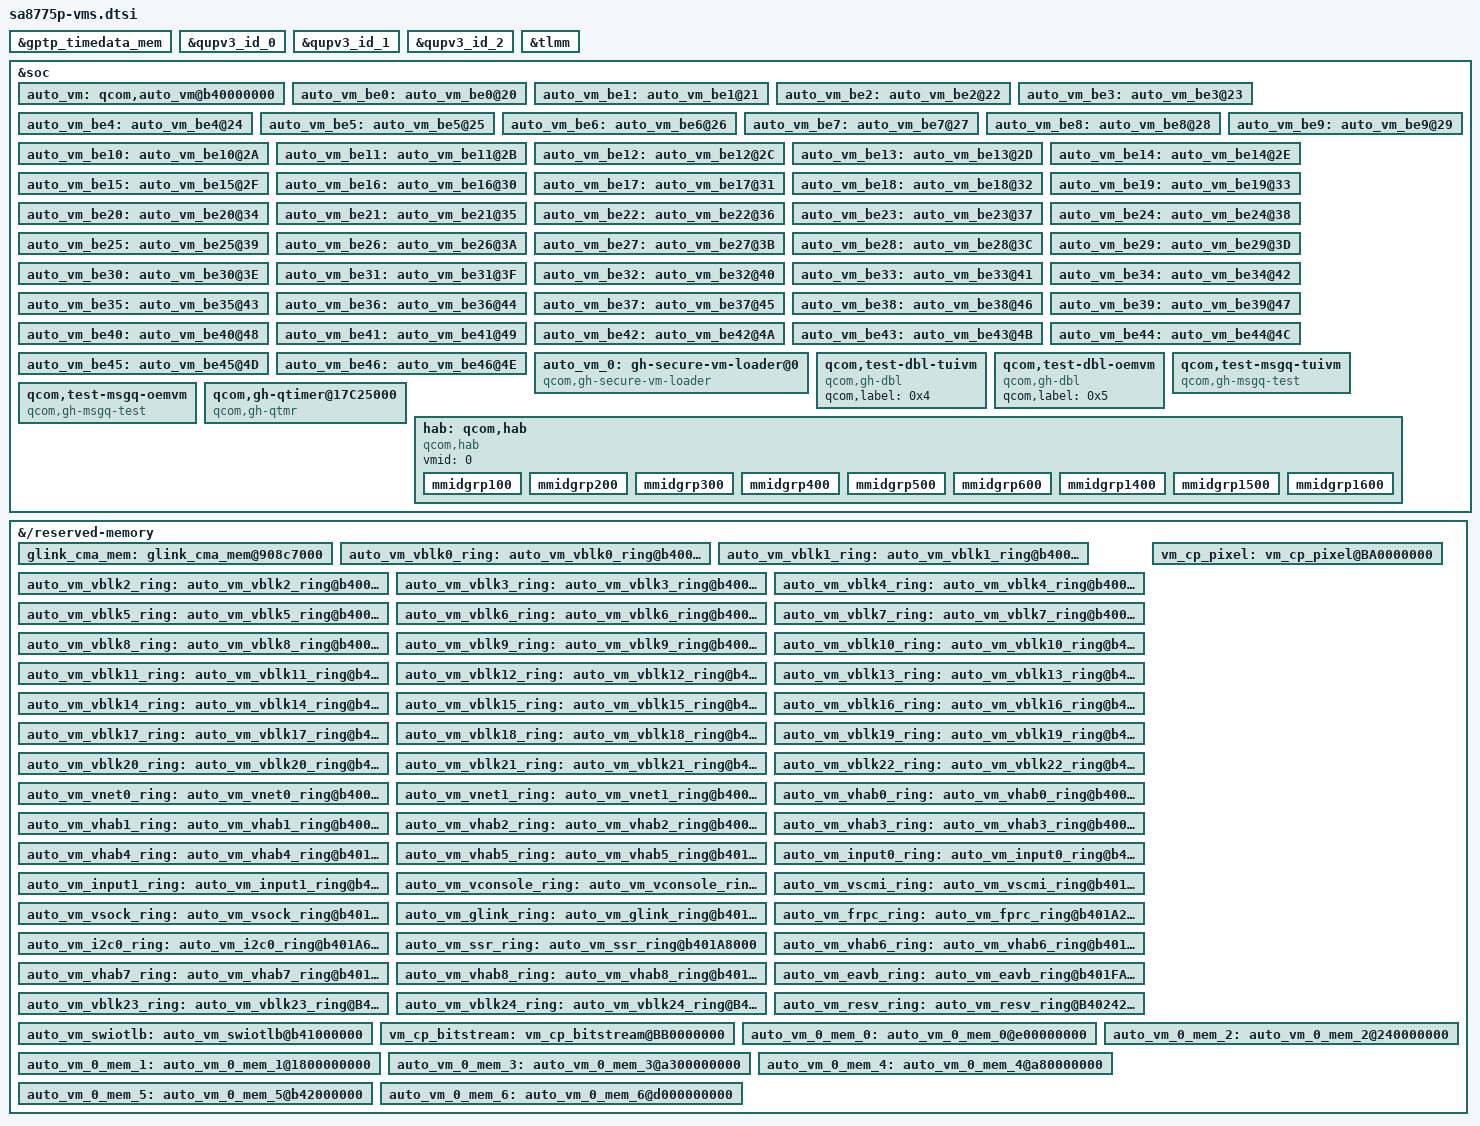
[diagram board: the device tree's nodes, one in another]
// SPDX-License-Identifier: BSD-3-Clause
/*
 * Copyright (c) Qualcomm Technologies, Inc. and/or its subsidiaries.
 */

#include <dt-bindings/firmware/qcom-shmem.h>
#include "sa8775p-vms-uscmi.dtsi"

&gptp_timedata_mem {
	qcom,is-shared;
	gunyah-label = <0x61>;
};

&qupv3_id_0 {
	reg = <0x0 0x009c0000 0x0 0x1000>;
	qcom,is-shared;
	qcom,is-iomem;
	gunyah-label = <0x7F>;
	qcom,dst-vmids = <AC_VM_GVM_1 AC_VM_GVM_2>;
	qcom,dst-perms = <QCOM_PERM_RW QCOM_PERM_RW>;
};

&qupv3_id_1 {
	reg = <0x0 0x00ac0000 0x0 0x1000>;
	qcom,is-shared;
	qcom,is-iomem;
	gunyah-label = <0x80>;
	qcom,dst-vmids = <AC_VM_GVM_1 AC_VM_GVM_2>;
	qcom,dst-perms = <QCOM_PERM_RW QCOM_PERM_RW>;
};

&qupv3_id_2 {
	reg = <0x0 0x008c0000 0x0 0x1000>;
	qcom,is-shared;
	qcom,is-iomem;
	gunyah-label = <0x81>;
	qcom,dst-vmids = <AC_VM_GVM_1 AC_VM_GVM_2>;
	qcom,dst-perms = <QCOM_PERM_RW QCOM_PERM_RW>;
};

&tlmm {
	qcom,is-shared;
	qcom,is-iomem;
	gunyah-label = <0x7E>;
	qcom,dst-vmids = <AC_VM_GVM_1 AC_VM_GVM_2>;
	qcom,dst-perms = <QCOM_PERM_RW QCOM_PERM_RW>;
};

&soc {
	auto_vm: qcom,auto_vm@b40000000 {
		reg = <0xb 0x40000000 0x0 0x3000000>;
		vm_name = "autoghgvm";
		shared-buffers = <&auto_vm_vblk0_ring
				&auto_vm_vblk1_ring
				&auto_vm_vblk2_ring
				&auto_vm_vblk3_ring
				&auto_vm_vblk4_ring
				&auto_vm_vblk5_ring
				&auto_vm_vblk6_ring
				&auto_vm_vblk7_ring
				&auto_vm_vblk8_ring
				&auto_vm_vblk9_ring
				&auto_vm_vblk10_ring
				&auto_vm_vblk11_ring
				&auto_vm_vblk12_ring
				&auto_vm_vblk13_ring
				&auto_vm_vblk14_ring
				&auto_vm_vblk15_ring
				&auto_vm_vblk16_ring
				&auto_vm_vblk17_ring
				&auto_vm_vblk18_ring
				&auto_vm_vblk19_ring
				&auto_vm_vblk20_ring
				&auto_vm_vblk21_ring
				&auto_vm_vblk22_ring
				&auto_vm_vblk23_ring
				&auto_vm_vblk24_ring
				&auto_vm_vnet0_ring
				&auto_vm_vnet1_ring
				&auto_vm_vhab0_ring
				&auto_vm_vhab1_ring
				&auto_vm_vhab2_ring
				&auto_vm_vhab3_ring
				&auto_vm_vhab4_ring
				&auto_vm_vhab5_ring
				&auto_vm_vhab6_ring
				&auto_vm_vhab7_ring
				&auto_vm_vhab8_ring
				&auto_vm_input0_ring
				&auto_vm_input1_ring
				&auto_vm_vconsole_ring
				&auto_vm_vscmi_ring
				&auto_vm_vsock_ring
				&auto_vm_glink_ring
				&auto_vm_frpc_ring
				&auto_vm_i2c0_ring
				&auto_vm_ssr_ring
				&auto_vm_eavb_ring
				&auto_vm_resv_ring
				&auto_vm_swiotlb>;
	};

	auto_vm_be0: auto_vm_be0@20 {
		qcom,vm = <&auto_vm>;
		qcom,label = <0x20>;
	};

	auto_vm_be1: auto_vm_be1@21 {
		qcom,vm = <&auto_vm>;
		qcom,label = <0x21>;
	};

	auto_vm_be2: auto_vm_be2@22 {
		qcom,vm = <&auto_vm>;
		qcom,label = <0x22>;
	};

	auto_vm_be3: auto_vm_be3@23 {
		qcom,vm = <&auto_vm>;
		qcom,label = <0x23>;
	};

	auto_vm_be4: auto_vm_be4@24 {
		qcom,vm = <&auto_vm>;
		qcom,label = <0x24>;
	};

	auto_vm_be5: auto_vm_be5@25 {
		qcom,vm = <&auto_vm>;
		qcom,label = <0x25>;
	};

	auto_vm_be6: auto_vm_be6@26 {
		qcom,vm = <&auto_vm>;
		qcom,label = <0x26>;
	};

	auto_vm_be7: auto_vm_be7@27 {
		qcom,vm = <&auto_vm>;
		qcom,label = <0x27>;
	};

	auto_vm_be8: auto_vm_be8@28 {
		qcom,vm = <&auto_vm>;
		qcom,label = <0x28>;
	};

	auto_vm_be9: auto_vm_be9@29 {
		qcom,vm = <&auto_vm>;
		qcom,label = <0x29>;
	};

	auto_vm_be10: auto_vm_be10@2A {
		qcom,vm = <&auto_vm>;
		qcom,label = <0x2A>;
	};

	auto_vm_be11: auto_vm_be11@2B {
		qcom,vm = <&auto_vm>;
		qcom,label = <0x2B>;
	};

	auto_vm_be12: auto_vm_be12@2C {
		qcom,vm = <&auto_vm>;
		qcom,label = <0x2C>;
	};

	auto_vm_be13: auto_vm_be13@2D {
		qcom,vm = <&auto_vm>;
		qcom,label = <0x2D>;
	};

	auto_vm_be14: auto_vm_be14@2E {
		qcom,vm = <&auto_vm>;
		qcom,label = <0x2E>;
	};

	auto_vm_be15: auto_vm_be15@2F {
		qcom,vm = <&auto_vm>;
		qcom,label = <0x2F>;
	};

	auto_vm_be16: auto_vm_be16@30 {
		qcom,vm = <&auto_vm>;
		qcom,label = <0x30>;
	};

	auto_vm_be17: auto_vm_be17@31 {
		qcom,vm = <&auto_vm>;
		qcom,label = <0x31>;
	};

	auto_vm_be18: auto_vm_be18@32 {
		qcom,vm = <&auto_vm>;
		qcom,label = <0x32>;
	};

	auto_vm_be19: auto_vm_be19@33 {
		qcom,vm = <&auto_vm>;
		qcom,label = <0x33>;
	};

	auto_vm_be20: auto_vm_be20@34 {
		qcom,vm = <&auto_vm>;
		qcom,label = <0x34>;
	};

	auto_vm_be21: auto_vm_be21@35 {
		qcom,vm = <&auto_vm>;
		qcom,label = <0x35>;
	};

	auto_vm_be22: auto_vm_be22@36 {
		qcom,vm = <&auto_vm>;
		qcom,label = <0x36>;
	};

	auto_vm_be23: auto_vm_be23@37 {
		qcom,vm = <&auto_vm>;
		qcom,label = <0x37>;
	};

	auto_vm_be24: auto_vm_be24@38 {
		qcom,vm = <&auto_vm>;
		qcom,label = <0x38>;
	};

	auto_vm_be25: auto_vm_be25@39 {
		qcom,vm = <&auto_vm>;
		qcom,label = <0x39>;
	};

	auto_vm_be26: auto_vm_be26@3A {
		qcom,vm = <&auto_vm>;
		qcom,label = <0x3A>;
	};

	auto_vm_be27: auto_vm_be27@3B {
		qcom,vm = <&auto_vm>;
		qcom,label = <0x3B>;
	};

	auto_vm_be28: auto_vm_be28@3C {
		qcom,vm = <&auto_vm>;
		qcom,label = <0x3C>;
	};

	auto_vm_be29: auto_vm_be29@3D {
		qcom,vm = <&auto_vm>;
		qcom,label = <0x3D>;
	};

	auto_vm_be30: auto_vm_be30@3E {
		qcom,vm = <&auto_vm>;
		qcom,label = <0x3E>;
	};

	auto_vm_be31: auto_vm_be31@3F {
		qcom,vm = <&auto_vm>;
		qcom,label = <0x3F>;
	};

	auto_vm_be32: auto_vm_be32@40 {
		qcom,vm = <&auto_vm>;
		qcom,label = <0x40>;
	};

	auto_vm_be33: auto_vm_be33@41 {
		qcom,vm = <&auto_vm>;
		qcom,label = <0x41>;
	};

	auto_vm_be34: auto_vm_be34@42 {
		qcom,vm = <&auto_vm>;
		qcom,label = <0x42>;
	};

	auto_vm_be35: auto_vm_be35@43 {
		qcom,vm = <&auto_vm>;
		qcom,label = <0x43>;
	};

	auto_vm_be36: auto_vm_be36@44 {
		qcom,vm = <&auto_vm>;
		qcom,label = <0x44>;
	};

	auto_vm_be37: auto_vm_be37@45 {
		qcom,vm = <&auto_vm>;
		qcom,label = <0x45>;
	};

	auto_vm_be38: auto_vm_be38@46 {
		qcom,vm = <&auto_vm>;
		qcom,label = <0x46>;
	};

	auto_vm_be39: auto_vm_be39@47 {
		qcom,vm = <&auto_vm>;
		qcom,label = <0x47>;
	};

	auto_vm_be40: auto_vm_be40@48 {
		qcom,vm = <&auto_vm>;
		qcom,label = <0x48>;
	};

	auto_vm_be41: auto_vm_be41@49 {
		qcom,vm = <&auto_vm>;
		qcom,label = <0x49>;
	};

	auto_vm_be42: auto_vm_be42@4A {
		qcom,vm = <&auto_vm>;
		qcom,label = <0x4A>;
	};

	auto_vm_be43: auto_vm_be43@4B {
		qcom,vm = <&auto_vm>;
		qcom,label = <0x4B>;
	};

	auto_vm_be44: auto_vm_be44@4C {
		qcom,vm = <&auto_vm>;
		qcom,label = <0x4C>;
	};

	auto_vm_be45: auto_vm_be45@4D {
		qcom,vm = <&auto_vm>;
		qcom,label = <0x4D>;
	};

	auto_vm_be46: auto_vm_be46@4E {
		qcom,vm = <&auto_vm>;
		qcom,label = <0x4E>;
	};

	auto_vm_0: gh-secure-vm-loader@0 {
		compatible = "qcom,gh-secure-vm-loader";
		qcom,pas-id = <44>;
		qcom,vmid = <52>;
		qcom,firmware-name = "autoghgvm";
		qcom,firmware-index = <0>;
		memory-region = <&auto_vm_0_mem_0 &auto_vm_0_mem_1 &auto_vm_0_mem_2 &auto_vm_0_mem_3 &auto_vm_0_mem_4 &auto_vm_0_mem_5 &auto_vm_0_mem_6>;
		shared-regions = <&glink_cma_mem &gptp_timedata_mem &vm_cp_pixel &vm_cp_bitstream &tlmm &qupv3_id_0 &qupv3_id_1 &qupv3_id_2>;
		enable-gvm-dump;
		virtio-backends = <&auto_vm_be0
				&auto_vm_be1
				&auto_vm_be2
				&auto_vm_be3
				&auto_vm_be4
				&auto_vm_be5
				&auto_vm_be6
				&auto_vm_be7
				&auto_vm_be8
				&auto_vm_be9
				&auto_vm_be10
				&auto_vm_be11
				&auto_vm_be12
				&auto_vm_be13
				&auto_vm_be14
				&auto_vm_be15
				&auto_vm_be16
				&auto_vm_be17
				&auto_vm_be18
				&auto_vm_be19
				&auto_vm_be20
				&auto_vm_be21
				&auto_vm_be22
				&auto_vm_be23
				&auto_vm_be24
				&auto_vm_be25
				&auto_vm_be26
				&auto_vm_be27
				&auto_vm_be28
				&auto_vm_be29
				&auto_vm_be30
				&auto_vm_be31
				&auto_vm_be32
				&auto_vm_be33
				&auto_vm_be34
				&auto_vm_be35
				&auto_vm_be36
				&auto_vm_be37
				&auto_vm_be38
				&auto_vm_be39
				&auto_vm_be40
				&auto_vm_be41
				&auto_vm_be42
				&auto_vm_be43
				&auto_vm_be44
				&auto_vm_be45
				&auto_vm_be46
				>;
	};

	qcom,test-dbl-tuivm {
		compatible = "qcom,gh-dbl";
		qcom,label = <0x4>;
	};

	qcom,test-dbl-oemvm {
		compatible = "qcom,gh-dbl";
		qcom,label = <0x5>;
	};

	qcom,test-msgq-tuivm {
		compatible = "qcom,gh-msgq-test";
		gunyah-label = <4>;
		qcom,primary;
	};

	qcom,test-msgq-oemvm {
		compatible = "qcom,gh-msgq-test";
		gunyah-label = <5>;
		qcom,primary;
	};

	qcom,gh-qtimer@17C25000 {
		compatible = "qcom,gh-qtmr";
		reg = <0x0 0x17C25000 0x0 0x1000>;
		reg-names = "qtmr-base";
		interrupts = <GIC_SPI 10 IRQ_TYPE_LEVEL_HIGH>;
		interrupt-names = "qcom,qtmr-intr";
		qcom,primary;
	};
};

&{/reserved-memory} {
	#address-cells = <2>;
	#size-cells = <2>;
	ranges;

	glink_cma_mem: glink_cma_mem@908c7000 {
		no-map;
		reg = <0x0 0x908c7000 0x0 0x12000>;
		qcom,dst-vmids = <AC_VM_CDSP_Q6_ELF>;
		qcom,dst-perms = <QCOM_PERM_RWX>;
		gunyah-label = <0x60>;
	};

	auto_vm_vblk0_ring: auto_vm_vblk0_ring@b40000000 {
		no-map;
		reg = <0xb 0x40000000 0x0 0x4000>;
		gunyah-label = <0x20>;
	};

	auto_vm_vblk1_ring: auto_vm_vblk1_ring@b40004000 {
		no-map;
		reg = <0xb 0x40004000 0x0 0x4000>;
		gunyah-label = <0x21>;
	};

	auto_vm_vblk2_ring: auto_vm_vblk2_ring@b40008000 {
		no-map;
		reg = <0xb 0x40008000 0x0 0x4000>;
		gunyah-label = <0x22>;
	};

	auto_vm_vblk3_ring: auto_vm_vblk3_ring@b4000C000 {
		no-map;
		reg = <0xb 0x4000C000 0x0 0x4000>;
		gunyah-label = <0x23>;
	};

	auto_vm_vblk4_ring: auto_vm_vblk4_ring@b40010000 {
		no-map;
		reg = <0xb 0x40010000 0x0 0x4000>;
		gunyah-label = <0x24>;
	};

	auto_vm_vblk5_ring: auto_vm_vblk5_ring@b40014000 {
		no-map;
		reg = <0xb 0x40014000 0x0 0x4000>;
		gunyah-label = <0x25>;
	};

	auto_vm_vblk6_ring: auto_vm_vblk6_ring@b40018000 {
		no-map;
		reg = <0xb 0x40018000 0x0 0x4000>;
		gunyah-label = <0x26>;
	};

	auto_vm_vblk7_ring: auto_vm_vblk7_ring@b4001C000 {
		no-map;
		reg = <0xb 0x4001C000 0x0 0x4000>;
		gunyah-label = <0x27>;
	};

	auto_vm_vblk8_ring: auto_vm_vblk8_ring@b40020000 {
		no-map;
		reg = <0xb 0x40020000 0x0 0x4000>;
		gunyah-label = <0x28>;
	};

	auto_vm_vblk9_ring: auto_vm_vblk9_ring@b40024000 {
		no-map;
		reg = <0xb 0x40024000 0x0 0x4000>;
		gunyah-label = <0x29>;
	};

	auto_vm_vblk10_ring: auto_vm_vblk10_ring@b40028000 {
		no-map;
		reg = <0xb 0x40028000 0x0 0x4000>;
		gunyah-label = <0x2A>;
	};

	auto_vm_vblk11_ring: auto_vm_vblk11_ring@b4002C000 {
		no-map;
		reg = <0xb 0x4002C000 0x0 0x4000>;
		gunyah-label = <0x2B>;
	};

	auto_vm_vblk12_ring: auto_vm_vblk12_ring@b40030000 {
		no-map;
		reg = <0xb 0x40030000 0x0 0x4000>;
		gunyah-label = <0x2C>;
	};

	auto_vm_vblk13_ring: auto_vm_vblk13_ring@b40034000 {
		no-map;
		reg = <0xb 0x40034000 0x0 0x4000>;
		gunyah-label = <0x2D>;
	};

	auto_vm_vblk14_ring: auto_vm_vblk14_ring@b40038000 {
		no-map;
		reg = <0xb 0x40038000 0x0 0x4000>;
		gunyah-label = <0x2E>;
	};

	auto_vm_vblk15_ring: auto_vm_vblk15_ring@b4003C000 {
		no-map;
		reg = <0xb 0x4003C000 0x0 0x4000>;
		gunyah-label = <0x2F>;
	};

	auto_vm_vblk16_ring: auto_vm_vblk16_ring@b40040000 {
		no-map;
		reg = <0xb 0x40040000 0x0 0x4000>;
		gunyah-label = <0x30>;
	};

	auto_vm_vblk17_ring: auto_vm_vblk17_ring@b40044000 {
		no-map;
		reg = <0xb 0x40044000 0x0 0x4000>;
		gunyah-label = <0x31>;
	};

	auto_vm_vblk18_ring: auto_vm_vblk18_ring@b40048000 {
		no-map;
		reg = <0xb 0x40048000 0x0 0x4000>;
		gunyah-label = <0x32>;
	};

	auto_vm_vblk19_ring: auto_vm_vblk19_ring@b4004C000 {
		no-map;
		reg = <0xb 0x4004C000 0x0 0x4000>;
		gunyah-label = <0x33>;
	};

	auto_vm_vblk20_ring: auto_vm_vblk20_ring@b40050000 {
		no-map;
		reg = <0xb 0x40050000 0x0 0x4000>;
		gunyah-label = <0x34>;
	};

	auto_vm_vblk21_ring: auto_vm_vblk21_ring@b40054000 {
		no-map;
		reg = <0xb 0x40054000 0x0 0x4000>;
		gunyah-label = <0x35>;
	};

	auto_vm_vblk22_ring: auto_vm_vblk22_ring@b40058000 {
		no-map;
		reg = <0xb 0x40058000 0x0 0x4000>;
		gunyah-label = <0x36>;
	};

	auto_vm_vnet0_ring: auto_vm_vnet0_ring@b4005C000 {
		no-map;
		reg = <0xb 0x4005C000 0x0 0x8000>;
		gunyah-label = <0x37>;
	};

	auto_vm_vnet1_ring: auto_vm_vnet1_ring@b40064000 {
		no-map;
		reg = <0xb 0x40064000 0x0 0x8000>;
		gunyah-label = <0x38>;
	};

	auto_vm_vhab0_ring: auto_vm_vhab0_ring@b4006C000 {
		no-map;
		reg = <0xb 0x4006C000 0x0 0x10000>;
		gunyah-label = <0x39>;
	};

	auto_vm_vhab1_ring: auto_vm_vhab1_ring@b4007C000 {
		no-map;
		reg = <0xb 0x4007C000 0x0 0x10000>;
		gunyah-label = <0x3A>;
	};

	auto_vm_vhab2_ring: auto_vm_vhab2_ring@b4008C000 {
		no-map;
		reg = <0xb 0x4008C000 0x0 0x40000>;
		gunyah-label = <0x3B>;
	};

	auto_vm_vhab3_ring: auto_vm_vhab3_ring@b400CC000 {
		no-map;
		reg = <0xb 0x400CC000 0x0 0x50000>;
		gunyah-label = <0x3C>;
	};

	auto_vm_vhab4_ring: auto_vm_vhab4_ring@b4011C000 {
		no-map;
		reg = <0xb 0x4011C000 0x0 0x30000>;
		gunyah-label = <0x3D>;
	};

	auto_vm_vhab5_ring: auto_vm_vhab5_ring@b4014C000 {
		no-map;
		reg = <0xb 0x4014C000 0x0 0x30000>;
		gunyah-label = <0x3E>;
	};

	auto_vm_input0_ring: auto_vm_input0_ring@b4017C000 {
		no-map;
		reg = <0xb 0x4017C000 0x0 0x4000>;
		gunyah-label = <0x3F>;
	};

	auto_vm_input1_ring: auto_vm_input1_ring@b40180000 {
		no-map;
		reg = <0xb 0x40180000 0x0 0x4000>;
		gunyah-label = <0x40>;
	};

	auto_vm_vconsole_ring: auto_vm_vconsole_ring@b40184000 {
		no-map;
		reg = <0xb 0x40184000 0x0 0x8000>;
		gunyah-label = <0x41>;
	};

	auto_vm_vscmi_ring: auto_vm_vscmi_ring@b4018C000 {
		no-map;
		reg = <0xb 0x4018C000 0x0 0x8000>;
		gunyah-label = <0x42>;
	};

	auto_vm_vsock_ring: auto_vm_vsock_ring@b40194000 {
		no-map;
		reg = <0xb 0x40194000 0x0 0xC000>;
		gunyah-label = <0x43>;
	};

	auto_vm_glink_ring: auto_vm_glink_ring@b401A0000 {
		no-map;
		reg = <0xb 0x401A0000 0x0 0x2000>;
		gunyah-label = <0x44>;
	};

	auto_vm_frpc_ring: auto_vm_fprc_ring@b401A2000 {
		no-map;
		reg = <0xb 0x401A2000 0x0 0x4000>;
		gunyah-label = <0x45>;
	};

	auto_vm_i2c0_ring: auto_vm_i2c0_ring@b401A6000 {
		no-map;
		reg = <0xb 0x401A6000 0x0 0x2000>;
		gunyah-label = <0x46>;
	};

	auto_vm_ssr_ring: auto_vm_ssr_ring@b401A8000 {
		no-map;
		reg = <0xb 0x401A8000 0x0 0x2000>;
		gunyah-label = <0x47>;
	};

	auto_vm_vhab6_ring: auto_vm_vhab6_ring@b401AA000 {
		no-map;
		reg = <0xb 0x401AA000 0x0 0x10000>;
		gunyah-label = <0x48>;
	};

	auto_vm_vhab7_ring: auto_vm_vhab7_ring@b401BA000 {
		no-map;
		reg = <0xb 0x401BA000 0x0 0x10000>;
		gunyah-label = <0x49>;
	};

	auto_vm_vhab8_ring: auto_vm_vhab8_ring@b401CA000 {
		no-map;
		reg = <0xb 0x401CA000 0x0 0x30000>;
		gunyah-label = <0x4A>;
	};

	auto_vm_eavb_ring: auto_vm_eavb_ring@b401FA000 {
		no-map;
		reg = <0xb 0x401FA000 0x0 0x40000>;
		gunyah-label = <0x4B>;
	};

	auto_vm_vblk23_ring: auto_vm_vblk23_ring@B4023A000 {
		no-map;
		reg = <0xB 0x4023A000 0x0 0x4000>;
		gunyah-label = <0x4C>;
	};

	auto_vm_vblk24_ring: auto_vm_vblk24_ring@B4023E000 {
		no-map;
		reg = <0xB 0x4023E000 0x0 0x4000>;
		gunyah-label = <0x4D>;
	};

	auto_vm_resv_ring: auto_vm_resv_ring@B40242000 {
		no-map;
		reg = <0xB 0x40242000 0x0 0xDBE000>;
		gunyah-label = <0x4E>;
	};

	auto_vm_swiotlb: auto_vm_swiotlb@b41000000 {
		no-map;
		reg = <0xb 0x41000000 0x0 0x2000000>;
		gunyah-label = <0x50>;
	};

	vm_cp_pixel: vm_cp_pixel@BA0000000 {
		no-map;
		reg = <0xB 0xA0000000 0x0 0x10000000>;
		gunyah-label = <0xC0A>;
		qcom,is-phantom;
	};

	vm_cp_bitstream: vm_cp_bitstream@BB0000000 {
		no-map;
		reg = <0xB 0xB0000000 0x0 0x10000000>;
		gunyah-label = <0xC09>;
		qcom,is-phantom;
	};

	auto_vm_0_mem_0: auto_vm_0_mem_0@e00000000 {
		no-map;
		reg = <0x0 0xE0000000 0x0 0x20000000>;
	};

	auto_vm_0_mem_1: auto_vm_0_mem_1@1800000000 {
		no-map;
		reg = <0x1 0x80000000 0x0 0xC0000000>;
	};

	auto_vm_0_mem_2: auto_vm_0_mem_2@240000000 {
		no-map;
		reg = <0x2 0x40000000 0x0 0xC0000000>;
	};

	auto_vm_0_mem_3: auto_vm_0_mem_3@a300000000 {
		no-map;
		reg = <0xA 0x30000000 0x0 0x50000000>;
	};

	auto_vm_0_mem_4: auto_vm_0_mem_4@a80000000 {
		no-map;
		reg = <0xA 0x80000000 0x0 0xC0000000>;
	};

	auto_vm_0_mem_5: auto_vm_0_mem_5@b42000000 {
		no-map;
		reg = <0xB 0x43000000 0x0 0x5D000000>;
	};

	auto_vm_0_mem_6: auto_vm_0_mem_6@d000000000 {
		no-map;
		reg = <0xD 0x00000000 0x0 0xC0000000>;
	};
};

&soc {
	hab: qcom,hab {
		compatible = "qcom,hab";
		vmid = <0>;

		mmidgrp100: mmidgrp100 {
			grp-start-id = <100>;
			role = "be";
			remote-vmids = <2>;
		};

		mmidgrp200: mmidgrp200 {
			grp-start-id = <200>;
			role = "be";
			remote-vmids = <2>;
		};

		mmidgrp300: mmidgrp300 {
			grp-start-id = <300>;
			role = "be";
			remote-vmids = <2>;
		};

		mmidgrp400: mmidgrp400 {
			grp-start-id = <400>;
			role = "be";
			remote-vmids = <2>;
		};

		mmidgrp500: mmidgrp500 {
			grp-start-id = <500>;
			role = "be";
			remote-vmids = <2>;
		};

		mmidgrp600: mmidgrp600 {
			grp-start-id = <600>;
			role = "be";
			remote-vmids = <2>;
		};

		mmidgrp1400: mmidgrp1400 {
			grp-start-id = <1400>;
			role = "be";
			remote-vmids = <2>;
		};

		mmidgrp1500: mmidgrp1500 {
			grp-start-id = <1500>;
			role = "be";
			remote-vmids = <2>;
		};

		mmidgrp1600: mmidgrp1600 {
			grp-start-id = <1600>;
			role = "be";
			remote-vmids = <2>;
		};
	};
};
